# ADuCM302x register map
Vendor: Analog Devices; Series: ADuCM302x; File version: 1p0
CPU: CM3 r0p1, little endian, no MPU, no FPU, 3 interrupt priority bits
Registers are 32-bit, read-write, reset 0x0 unless marked. A register's access mark holds for its fields unless they carry their own. Offsets are from the block's base; [hi:lo] are bit positions; {n}, {i} and the like mark numbered series.

## RTC0 — Real-Time Clock
Base 0x40001000
Same registers: RTC1 0x40001400
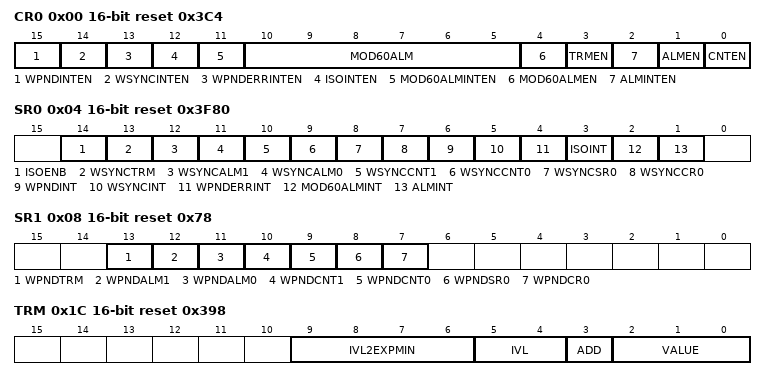
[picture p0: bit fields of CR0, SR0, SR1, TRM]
0x00 CR0 16-bit reset 0x3C4 — RTC Control 0
  [15] WPNDINTEN — Enable Write Pending Sourced Interrupts to the CPU
  [14] WSYNCINTEN — Enable Write Synchronization Sourced Interrupts to the CPU
  [13] WPNDERRINTEN — Enable Write Pending Error Sourced Interrupts to the CPU When an RTC Register-write Pending Error Occurs
  [12] ISOINTEN — Enable ISOINT Sourced Interrupts to the CPU When Isolation of the RTC Power Domain is Activated and Subsequently De-activated
  [11] MOD60ALMINTEN — Enable Periodic Modulo-60 RTC Alarm Sourced Interrupts to the CPU
  [10:5] MOD60ALM range 0x00000000..0x0000003F — Periodic, Modulo-60 Alarm Time in Prescaled RTC Time Units Beyond a Modulo-60 Boundary
  [4] MOD60ALMEN — Enable RTC Modulo-60 Counting of Time Past a Modulo-60 Boundary
  [3] TRMEN — Enable RTC Digital Trimming
  [2] ALMINTEN — Enable ALMINT Sourced Alarm Interrupts to the CPU
  [1] ALMEN — Enable the RTC Alarm (Absolute) Operation
  [0] CNTEN — Global Enable for the RTC
0x04 SR0 16-bit reset 0x3F80 — RTC Status 0
  [14] ISOENB ro — Visibility of 32kHz Sourced Registers
  [13] WSYNCTRM ro — Synchronisation Status of Posted Writes to TRM
  [12] WSYNCALM1 ro — Synchronisation Status of Posted Writes to ALM1
  [11] WSYNCALM0 ro — Synchronisation Status of Posted Writes to ALM0
  [10] WSYNCCNT1 ro — Synchronisation Status of Posted Writes to CNT1
  [9] WSYNCCNT0 ro — Synchronisation Status of Posted Writes to CNT0
  [8] WSYNCSR0 ro — Synchronisation Status of Posted Writes to SR0
  [7] WSYNCCR0 ro — Synchronisation Status of Posted Writes to CR0
  [6] WPNDINT — Write Pending Interrupt
  [5] WSYNCINT — Write Synchronisation Interrupt
  [4] WPNDERRINT — Write Pending Error Interrupt Source
  [3] ISOINT — RTC Power-Domain Isolation Interrupt Source
  [2] MOD60ALMINT — Modulo-60 RTC Alarm Interrupt Source
  [1] ALMINT — Alarm Interrupt Source
0x08 SR1 16-bit reset 0x78 — RTC Status 1
  [13] WPNDTRM ro — Pending Status of Posted Writes to TRM
  [12] WPNDALM1 ro — Pending Status of Posted Writes to ALM1
  [11] WPNDALM0 ro — Pending Status of Posted Writes to ALM0
  [10] WPNDCNT1 ro — Pending Status of Posted Writes to CNT1
  [9] WPNDCNT0 ro — Pending Status of Posted Writes to CNT0
  [8] WPNDSR0 ro — Pending Status of Posted Clearances of Interrupt Sources in SR0
  [7] WPNDCR0 ro — Pending Status of Posted Writes to CR0
0x0C CNT0 16-bit — RTC Count 0
  [15:0] VALUE range 0x00000000..0x0000FFFF — Lower 16 Prescaled (Non-Fractional) Bits of the RTC Real-Time Count
0x10 CNT1 16-bit — RTC Count 1
  [15:0] VALUE range 0x00000000..0x0000FFFF — Upper 16 Prescaled (Non-Fractional) Bits of the RTC Real-Time Count
0x14 ALM0 16-bit reset 0xFFFF — RTC Alarm 0
  [15:0] VALUE range 0x00000000..0x0000FFFF — Lower 16 Prescaled (i.e. Non-Fractional) Bits of the RTC Alarm Target Time
0x18 ALM1 16-bit reset 0xFFFF — RTC Alarm 1
  [15:0] VALUE range 0x00000000..0x0000FFFF — Upper 16 Prescaled (Non-Fractional) Bits of the RTC Alarm Target Time
0x1C TRM 16-bit reset 0x398 — RTC Trim
  [9:6] IVL2EXPMIN range 0x00000000..0x0000000F — Minimum Power-of-two Interval of Prescaled RTC Time Units Which TRM:TRMIVL TRMIVL Can Select
  [5:4] IVL — Trim Interval in Prescaled RTC Time Units
  [3] ADD — Trim Polarity
  [2:0] VALUE — Trim Value in Prescaled RTC Time Units to Be Added or Subtracted from the RTC Count at the End of a Periodic Interval Selected by TRM:TRMIVL
0x20 GWY 16-bit — RTC Gateway
  [15:0] SWKEY wo range 0x00000000..0x0000FFFF — Software-keyed Command Issued by the CPU
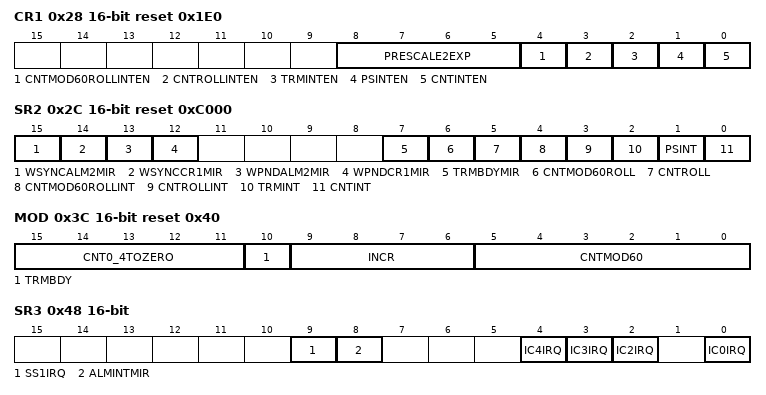
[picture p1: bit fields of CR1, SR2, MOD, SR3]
0x28 CR1 16-bit reset 0x1E0 — RTC Control 1
  [8:5] PRESCALE2EXP — Prescale Power of 2 Division Factor for the RTC Base Clock
  [4] CNTMOD60ROLLINTEN — Enable for the RTC Modulo-60 Count Roll-Over Interrupt Source, in SR2:RTCCNTMOD60ROLLINT
  [3] CNTROLLINTEN — Enable for the RTC Count Roll-Over Interrupt Source, in SR2:RTCCNTROLLINT
  [2] TRMINTEN — Enable for the RTC Trim Interrupt Source, in SR2:RTCTRMINT
  [1] PSINTEN — Enable for the Prescaled, Modulo-1 Interrupt Source, in SR2:RTCPSINT
  [0] CNTINTEN — Enable for the RTC Count Interrupt Source
0x2C SR2 16-bit reset 0xC000 — RTC Status 2
  [15] WSYNCALM2MIR ro — Synchronization Status of Posted Writes to ALM2
  [14] WSYNCCR1MIR ro — Synchronization Status of Posted Writes to CR1
  [13] WPNDALM2MIR ro — Pending Status of Posted Writes to ALM2
  [12] WPNDCR1MIR ro — Pending Status of Posted Writes to CR1
  [7] TRMBDYMIR ro — Mirror of MOD:RTCTRMBDY
  [6] CNTMOD60ROLL ro — RTC Count Modulo-60 Roll-Over
  [5] CNTROLL ro — RTC Count Roll-Over
  [4] CNTMOD60ROLLINT — RTC Modulo-60 Count Roll-Over Interrupt Source
  [3] CNTROLLINT — RTC Count Roll-Over Interrupt Source
  [2] TRMINT — RTC Trim Interrupt Source
  [1] PSINT — RTC Prescaled, Modulo-1 Boundary Interrupt Source
  [0] CNTINT — RTC Count Interrupt Source
0x30 SNAP0 16-bit — RTC Snapshot 0
  [15:0] VALUE ro — Constituent Part of the 47-bit Input Capture Channel 0, Containing a Sticky Snapshot of CNT0
0x34 SNAP1 16-bit — RTC Snapshot 1
  [15:0] VALUE ro — Part of the 47-bit Input Capture Channel 0 Containing a Sticky Snapshot of CNT1
0x38 SNAP2 16-bit — RTC Snapshot 2
  [14:0] VALUE ro — Part of the 47-bit Input Capture Channel 0 Containing a Sticky Snapshot of CNT2
0x3C MOD 16-bit reset 0x40 — RTC Modulo
  [15:11] CNT0_4TOZERO ro — Mirror of CNT0[4:0]
  [10] TRMBDY ro — Trim Boundary Indicator
  [9:6] INCR ro — Most Recent Increment Value Added to the RTC Count in CNT1 and CNT0
  [5:0] CNTMOD60 ro — Modulo-60 Value of the RTC Count: CNT1 and CNT0
0x40 CNT2 16-bit — RTC Count 2
  [14:0] VALUE ro — Fractional Bits of the RTC Real-Time Count
0x44 ALM2 16-bit — RTC Alarm 2
  [14:0] VALUE range 0x00000000..0x00007FFF — Fractional Bits of the Alarm Target Time
0x48 SR3 16-bit — RTC Status 3
  [9] SS1IRQ — Sticky Interrupt Source for SensorStrobe Channel 1
  [8] ALMINTMIR ro — Read-only Mirror of the ALMINT Interrupt Source in SR0 Register
  [4] IC4IRQ — Sticky Interrupt Source for the RTC Input Capture Channel 4
  [3] IC3IRQ — Sticky Interrupt Source for the RTC Input Capture Channel 3
  [2] IC2IRQ — Sticky Interrupt Source for the RTC Input Capture Channel 2
  [0] IC0IRQ — Sticky Interrupt Source for the RTC Input Capture Channel 0
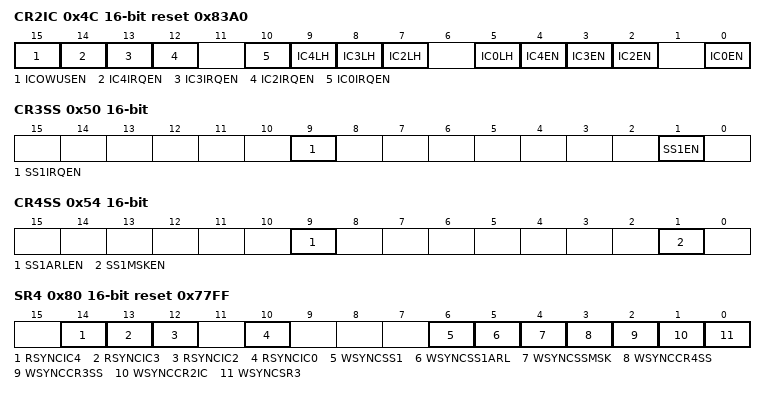
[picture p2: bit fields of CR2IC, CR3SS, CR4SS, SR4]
0x4C CR2IC 16-bit reset 0x83A0 — RTC Control 2 for Configuring Input Capture Channels
  [15] ICOWUSEN — Enable Overwrite of Unread Snapshots for All Input Capture Channels
  [14] IC4IRQEN — Interrupt Enable for the RTC Input Capture Channel 4
  [13] IC3IRQEN — Interrupt Enable for the RTC Input Capture Channel 3
  [12] IC2IRQEN — Interrupt Enable for the RTC Input Capture Channel 2
  [10] IC0IRQEN — Interrupt Enable for the RTC Input Capture Channel 0
  [9] IC4LH — Polarity of the Active-going Capture Edge for the Input Capture Channel 4
  [8] IC3LH — Polarity of the Active-going Capture Edge for the Input Capture Channel 3
  [7] IC2LH — Polarity of the Active-going Capture Edge for the Input Capture Channel 2
  [5] IC0LH — Polarity of the Active-Going Capture Edge for the RTC Input Capture Channel 0
  [4] IC4EN — Enable for the RTC Input Capture Channel 4
  [3] IC3EN — Enable for the RTC Input Capture Channel 3
  [2] IC2EN — Enable for the RTC Input Capture Channel 2
  [0] IC0EN — Enable for the RTC Input Capture Channel 0
0x50 CR3SS 16-bit — RTC Control 3 for Configuring SensorStrobe Channel
  [9] SS1IRQEN — Interrupt Enable for SensorStrobe Channel 1
  [1] SS1EN — Enable for SensorStrobe Channel 1
0x54 CR4SS 16-bit — RTC Control 4 for Configuring SensorStrobe Channel
  [9] SS1ARLEN — Enable for Auto-Reloading When SensorStrobe Match Occurs
  [1] SS1MSKEN — Enable for Thermometer-Code Masking of the SensorStrobe Channel 1
    0=NO_MSK (Do not apply a mask to SensorStrobe Channel 1 Register); 1=THERM_MSK (Apply thermometer decoded mask)
0x58 SSMSK 16-bit — RTC Mask for SensorStrobe Channel
  [15:0] SSMSK range 0x00000000..0x0000FFFF — Thermometer-Encoded Masks for SensorStrobe Channels
0x5C SS1ARL 16-bit — RTC Auto-Reload for SensorStrobe Channel 1
  [15:0] SS1ARL range 0x00000000..0x0000FFFF — Auto-Reload Value When SensorStrobe Match Occurs
{0x5C+4i} IC{i} 16-bit (i=2..4) — RTC Input Capture Channel {i}
  [15:0] IC{i} ro
0x70 SS1 16-bit reset 0x8000 — RTC SensorStrobe Channel 1
  [15:0] SS1 range 0x00000000..0x0000FFFF — SensorStrobe Channel 1
0x80 SR4 16-bit reset 0x77FF — RTC Status 4
  [14] RSYNCIC4 ro — Synchronization Status of Posted Reads of RTC Input Channel 4
  [13] RSYNCIC3 ro — Synchronization Status of Posted Reads of RTC Input Channel 3
  [12] RSYNCIC2 ro — Synchronization Status of Posted Reads of RTC Input Channel 2
  [10] RSYNCIC0 ro — Synchronization Status of Posted Reads of RTC Input Channel 0
  [6] WSYNCSS1 ro — Synchronization Status of Posted Writes to SensorStrobe Channel 1
  [5] WSYNCSS1ARL ro — Synchronization Status of Posted Writes to RTC Auto-Reload for SensorStrobe Channel 1 Register
  [4] WSYNCSSMSK ro — Synchronization Status of Posted Writes to Masks for SensorStrobe Channel Register
  [3] WSYNCCR4SS ro — Synchronization Status of Posted Writes to RTC Control 4 for Configuring SensorStrobe Channel Register
  [2] WSYNCCR3SS ro — Synchronization Status of Posted Writes to RTC Control 3 for Configuring SensorStrobe Channel Register
  [1] WSYNCCR2IC ro — Synchronization Status of Posted Writes to RTC Control 2 for Configuring Input Capture Channels Register
  [0] WSYNCSR3 ro — Synchronisation Status of Posted Writes to SR3
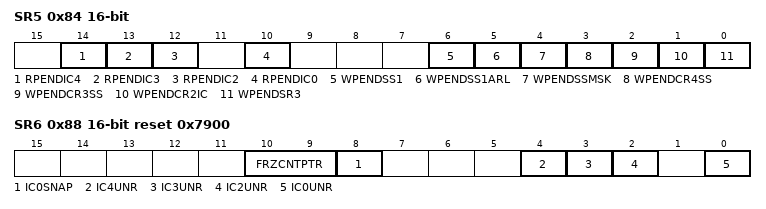
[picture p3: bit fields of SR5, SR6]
0x84 SR5 16-bit — RTC Status 5
  [14] RPENDIC4 ro — Pending Status of Posted Reads of IC4
  [13] RPENDIC3 ro — Pending Status of Posted Reads of IC3
  [12] RPENDIC2 ro — Pending Status of Posted Reads of IC2
  [10] RPENDIC0 ro — Pending Status of Posted Reads of Input Capture Channel 0
  [6] WPENDSS1 ro — Pending Status of Posted Writes to SensorStrobe Channel 1
  [5] WPENDSS1ARL ro — Pending Status of Posted Writes to RTC Auto-Reload for SensorStrobe Channel 1 Register
  [4] WPENDSSMSK ro — Pending Status of Posted Writes to RTC Masks for SensorStrobe Channel Register
  [3] WPENDCR4SS ro — Pending Status of Posted Writes to RTC Control 4 for Configuring SensorStrobe Channel Register
  [2] WPENDCR3SS ro — Pending Status of Posted Writes to RTC Control 3 for Configuring SensorStrobe Channel Register
  [1] WPENDCR2IC ro — Pending Status of Posted Writes to RTC Control 2 for Configuring Input Capture Channels Register
  [0] WPENDSR3 ro — Pending Status of Posted Clearances of Interrupt Sources in RTC Status 3 Register
0x88 SR6 16-bit reset 0x7900 — RTC Status 6
  [10:9] FRZCNTPTR ro — Pointer for the Triple-Read Sequence of FRZCNT
  [8] IC0SNAP ro — Confirmation That RTC Snapshot 0, 1, 2 Registers Reflect the Value of Input-Capture Channel RTC Input Capture Channel 0
  [4] IC4UNR ro — Sticky Unread Status of the Input Capture Channel 4
  [3] IC3UNR ro — Sticky Unread Status of the Input Capture Channel 3
  [2] IC2UNR ro — Sticky Unread Status of the Input Capture Channel 2
  [0] IC0UNR ro — Sticky Unread Status of the Input Capture Channel 0
0x8C SS1TGT 16-bit reset 0x8000 — RTC SensorStrobe Channel 1 Target
  [15:0] SS1TGT ro — Current Target Value for the SensorStrobe Channel 1
0x90 FRZCNT 16-bit — RTC Freeze Count
  [15:0] FRZCNT ro — RTC Freeze Count. Coherent, Triple 16-Bit Read of the 47-Bit RTC Count
